VERSION ""

NS_ :

BS_:

BU_: PCM TCM

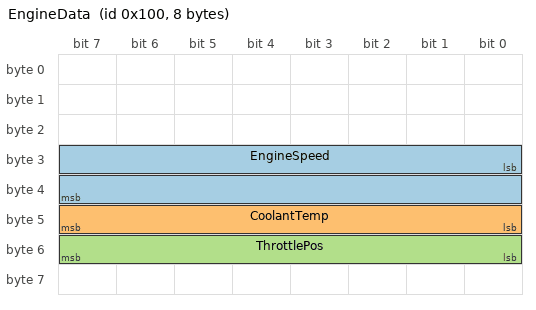
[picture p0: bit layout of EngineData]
BO_ 256 EngineData: 8 PCM
 SG_ EngineSpeed : 24|16@1+ (0.125,0) [0|8000] "rpm" TCM
 SG_ CoolantTemp : 40|8@1- (1,-40) [-40|215] "degC" TCM
 SG_ ThrottlePos : 48|8@1+ (0.3921568627,0) [0|100] "%" TCM

BO_ 512 StatusFlags: 8 PCM
 SG_ OilPressureLow : 7|1@1+ (1,0) [0|1] "" TCM
 SG_ CheckEngine : 15|1@1+ (1,0) [0|1] "" TCM

VAL_ 256 EngineSpeed 0 "Stopped" 4000 "Cruise" ;
